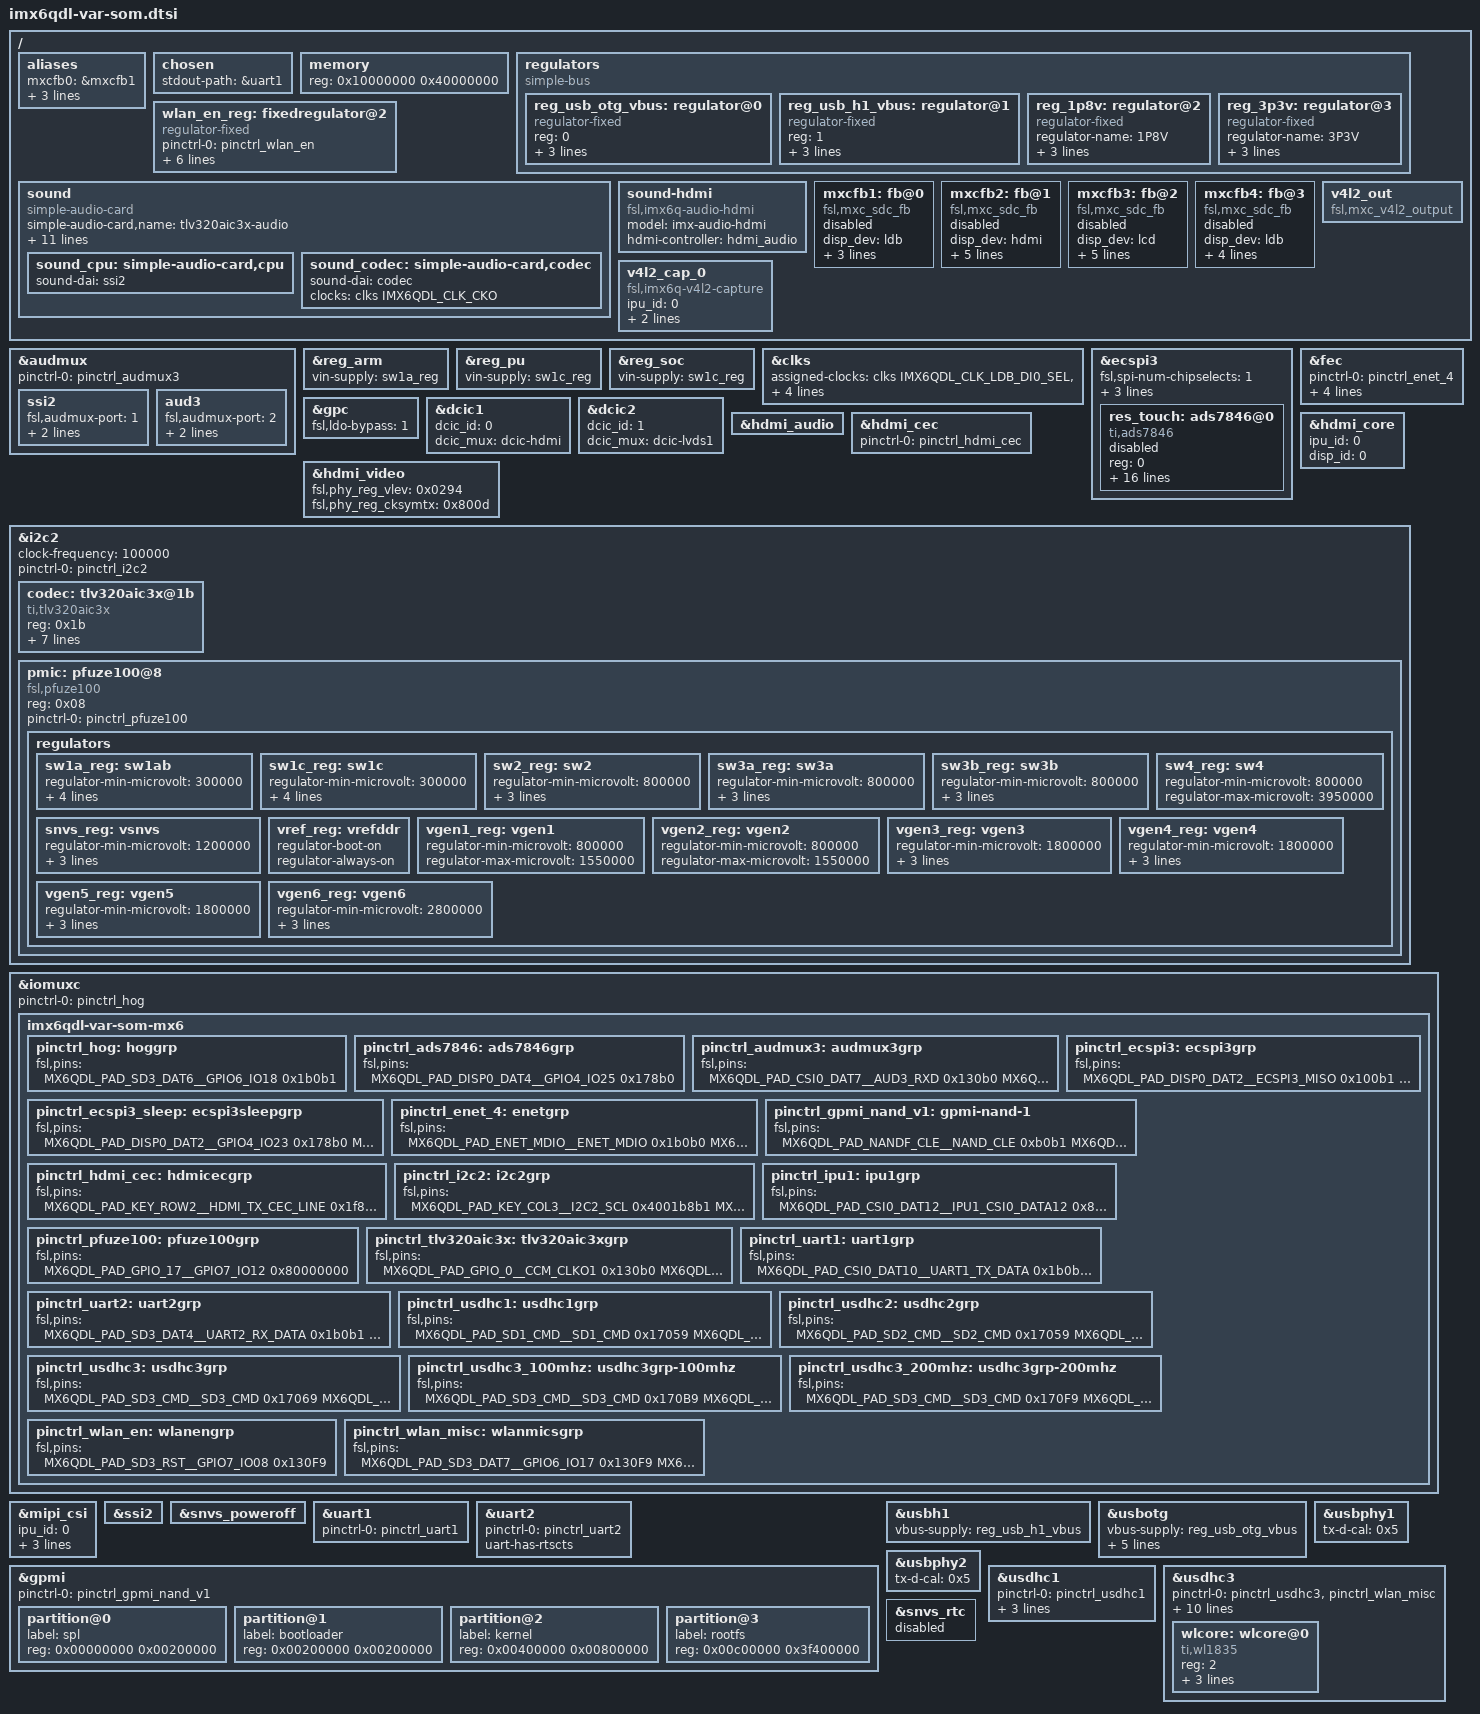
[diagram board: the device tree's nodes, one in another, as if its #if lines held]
/*
 * Copyright (C) 2015-2017 Variscite Ltd.
 *
 * This program is free software; you can redistribute it and/or modify
 * it under the terms of the GNU General Public License version 2 as
 * published by the Free Software Foundation.
 */

#include <dt-bindings/gpio/gpio.h>
#include <dt-bindings/input/input.h>
#include <dt-bindings/sound/fsl-imx-audmux.h>

/ {
	aliases {
		mxcfb0 = &mxcfb1;
		mxcfb1 = &mxcfb2;
		mxcfb2 = &mxcfb3;
		mxcfb3 = &mxcfb4;
	};

	chosen {
		stdout-path = &uart1;
	};

	memory: memory {
		reg = <0x10000000 0x40000000>;
	};

	regulators {
		compatible = "simple-bus";
		#address-cells = <1>;
		#size-cells = <0>;

		reg_usb_otg_vbus: regulator@0 {
			compatible = "regulator-fixed";
			reg = <0>;
			regulator-name = "usb_otg_vbus";
			regulator-min-microvolt = <5000000>;
			regulator-max-microvolt = <5000000>;
		};

		reg_usb_h1_vbus: regulator@1 {
			compatible = "regulator-fixed";
			reg = <1>;
			regulator-name = "usb_h1_vbus";
			regulator-min-microvolt = <5000000>;
			regulator-max-microvolt = <5000000>;
		};

		reg_1p8v: regulator@2 {
			compatible = "regulator-fixed";
			regulator-name = "1P8V";
			regulator-min-microvolt = <1800000>;
			regulator-max-microvolt = <1800000>;
			regulator-always-on;
		};

		reg_3p3v: regulator@3 {
			compatible = "regulator-fixed";
			regulator-name = "3P3V";
			regulator-min-microvolt = <3300000>;
			regulator-max-microvolt = <3300000>;
			regulator-always-on;
		};
	};

	wlan_en_reg: fixedregulator@2 {
		compatible = "regulator-fixed";
		pinctrl-names = "default";
		pinctrl-0 = <&pinctrl_wlan_en>;
		regulator-name = "wlan-en-regulator";
		regulator-min-microvolt = <1800000>;
		regulator-max-microvolt = <1800000>;

		/* WLAN_EN GPIO for this board - Bank5, pin13 */
		gpio = <&gpio7 8 0>;

		/* WLAN card specific delay */
		startup-delay-us = <70000>;
		enable-active-high;
	};

	sound {
		compatible = "simple-audio-card";
		simple-audio-card,name = "tlv320aic3x-audio";
		simple-audio-card,format = "i2s";
		simple-audio-card,bitclock-master = <&sound_codec>;
		simple-audio-card,frame-master = <&sound_codec>;
		simple-audio-card,widgets = "Headphone", "Headphone Jack",
					    "Line", "Line In Jack",
					    "Microphone", "DMic";
#ifdef HAVE_AUDIO_ENABLE_GPIO
		/* Sample use of gpio controlled amplifier:
		 * this is extremely useful to avoid the bump effect
		 * observed when connecting an amplifier to the HP OUT.
		 * The property "pa-gpios" must provide the enable GPIO.
		 */
		pa-gpios = <&gpio5 30 GPIO_ACTIVE_HIGH>;
		simple-audio-card,routing = "Headphone Jack", "Amplifier",
					    "Amplifier", "HPLOUT",
					    "Amplifier", "HPROUT",
					    "LINE1L", "Line In Jack",
					    "LINE1R", "Line In Jack",
					    "DMIC", "DMic";
#else
		simple-audio-card,routing = "Headphone Jack", "HPLOUT",
					    "Headphone Jack", "HPROUT",
					    "LINE1L", "Line In Jack",
					    "LINE1R", "Line In Jack",
					    "DMIC", "DMic";
#endif
		sound_cpu: simple-audio-card,cpu {
			sound-dai = <&ssi2>;
		};

		sound_codec: simple-audio-card,codec {
			sound-dai = <&codec>;
			clocks = <&clks IMX6QDL_CLK_CKO>;
		};
	};

	sound-hdmi {
		compatible = "fsl,imx6q-audio-hdmi",
			     "fsl,imx-audio-hdmi";
		model = "imx-audio-hdmi";
		hdmi-controller = <&hdmi_audio>;
	};

	mxcfb1: fb@0 {
		compatible = "fsl,mxc_sdc_fb";
		disp_dev = "ldb";
		default_bpp = <16>;
		int_clk = <0>;
		late_init = <0>;
		status = "disabled";
	};

	mxcfb2: fb@1 {
		compatible = "fsl,mxc_sdc_fb";
		disp_dev = "hdmi";
		interface_pix_fmt = "RGB24";
		mode_str ="1920x1080M@60";
		default_bpp = <24>;
		int_clk = <0>;
		late_init = <0>;
		status = "disabled";
	};

	mxcfb3: fb@2 {
		compatible = "fsl,mxc_sdc_fb";
		disp_dev = "lcd";
		interface_pix_fmt = "RGB565";
		mode_str ="CLAA-WVGA";
		default_bpp = <16>;
		int_clk = <0>;
		late_init = <0>;
		status = "disabled";
	};

	mxcfb4: fb@3 {
		compatible = "fsl,mxc_sdc_fb";
		disp_dev = "ldb";
		interface_pix_fmt = "RGB666";
		default_bpp = <16>;
		int_clk = <0>;
		late_init = <0>;
		status = "disabled";
	};

	v4l2_cap_0 {
		compatible = "fsl,imx6q-v4l2-capture";
		ipu_id = <0>;
		csi_id = <1>;
		mclk_source = <0>;
		status = "okay";
	};

	v4l2_out {
		compatible = "fsl,mxc_v4l2_output";
		status = "okay";
	};
};

&audmux {
	pinctrl-names = "default";
	pinctrl-0 = <&pinctrl_audmux3>;
	status = "okay";

	ssi2 {
		fsl,audmux-port = <1>;
		fsl,port-config = <
			(IMX_AUDMUX_V2_PTCR_SYN |
			IMX_AUDMUX_V2_PTCR_TFSDIR |
			IMX_AUDMUX_V2_PTCR_TFSEL(2) |
			IMX_AUDMUX_V2_PTCR_TCLKDIR |
			IMX_AUDMUX_V2_PTCR_TCSEL(2))
			IMX_AUDMUX_V2_PDCR_RXDSEL(2)
		>;
	};

	aud3 {
		fsl,audmux-port = <2>;
		fsl,port-config = <
			IMX_AUDMUX_V2_PTCR_SYN
			IMX_AUDMUX_V2_PDCR_RXDSEL(1)
		>;
	};
};

&reg_arm {
	vin-supply = <&sw1a_reg>;
};

&reg_pu {
	vin-supply = <&sw1c_reg>;
};

&reg_soc {
	vin-supply = <&sw1c_reg>;
};

&clks {
	assigned-clocks = <&clks IMX6QDL_CLK_LDB_DI0_SEL>,
			  <&clks IMX6QDL_CLK_LDB_DI1_SEL>;
	assigned-clock-parents = <&clks IMX6QDL_CLK_PLL2_PFD0_352M>,
				 <&clks IMX6QDL_CLK_PLL2_PFD0_352M>;
};

&ecspi3 {
	fsl,spi-num-chipselects = <1>;
	pinctrl-names = "default", "sleep";
	pinctrl-0 = <&pinctrl_ecspi3>;
	pinctrl-1 = <&pinctrl_ecspi3_sleep>;
	cs-gpios = <&gpio4 24 0>;
	status = "okay";

	/* Touch */
	res_touch: ads7846@0 {
		reg = <0>;	/* CS0 */
		compatible = "ti,ads7846";
		pinctrl-names = "default";
		pinctrl-0 = <&pinctrl_ads7846>;
		interrupt-parent = <&gpio4>;
		interrupts = <25 0>;
		spi-max-frequency = <1500000>;
		pendown-gpio = <&gpio4 25 0>;
		ti,x-min = /bits/ 16 <125>;
		ti,x-max = /bits/ 16 <4008>;
		ti,y-min = /bits/ 16 <282>;
		ti,y-max = /bits/ 16 <3864>;
		ti,x-plate-ohms = /bits/ 16 <180>;
		ti,pressure-max = /bits/ 16 <255>;
		ti,debounce-max = /bits/ 16 <10>;
		ti,debounce-tol = /bits/ 16 <3>;
		ti,debounce-rep = /bits/ 16 <1>;
		ti,settle-delay-usec = /bits/ 16 <150>;
		ti,keep-vref-on;
		status = "disabled";
	};
};

&fec {
	pinctrl-names = "default";
	pinctrl-0 = <&pinctrl_enet_4>;
	phy-mode = "rgmii";
	phy-reset-gpios = <&gpio1 25 0>;
	phy-reset-duration=<100>;
	phy-reset-on-resume;
	status = "okay";
};

&gpc {
	/* use ldo-bypass, u-boot will check it and configure */
	fsl,ldo-bypass = <1>;
};

&dcic1 {
	dcic_id = <0>;
	dcic_mux = "dcic-hdmi";
	status = "okay";
};

&dcic2 {
	dcic_id = <1>;
	dcic_mux = "dcic-lvds1";
	status = "okay";
};

&hdmi_audio {
	status = "okay";
};

&hdmi_cec {
	pinctrl-names = "default";
	pinctrl-0 = <&pinctrl_hdmi_cec>;
	status = "okay";
};

&hdmi_core {
	ipu_id = <0>;
	disp_id = <0>;
	status = "okay";
};

&hdmi_video {
	fsl,phy_reg_vlev = <0x0294>;
	fsl,phy_reg_cksymtx = <0x800d>;
	status = "okay";
};

&i2c2 {
	clock-frequency = <100000>;
	pinctrl-names = "default";
	pinctrl-0 = <&pinctrl_i2c2>;
	status = "okay";

	codec: tlv320aic3x@1b {
		compatible = "ti,tlv320aic3x";
		reg = <0x1b>;
		#sound-dai-cells = <0>;
		pinctrl-names = "default";
		pinctrl-0 = <&pinctrl_tlv320aic3x>;
		IOVDD-supply = <&reg_3p3v>;
		DVDD-supply = <&reg_1p8v>;
		AVDD-supply = <&reg_3p3v>;
		DRVDD-supply = <&reg_3p3v>;
		reset-gpios = <&gpio4 5 GPIO_ACTIVE_LOW>;
		ai3x-gpio-func = <
			0 /* AIC3X_GPIO1_FUNC_DISABLED */
			5 /* AIC3X_GPIO2_FUNC_DIGITAL_MIC_INPUT */
		>;
	};

	pmic: pfuze100@8 {
		compatible = "fsl,pfuze100";
		reg = <0x08>;
		pinctrl-names = "default";
		pinctrl-0 = <&pinctrl_pfuze100>;

		regulators {
			sw1a_reg: sw1ab {
				regulator-min-microvolt = <300000>;
				regulator-max-microvolt = <1875000>;
				regulator-boot-on;
				regulator-always-on;
				regulator-ramp-delay = <6250>;
			};

			sw1c_reg: sw1c {
				regulator-min-microvolt = <300000>;
				regulator-max-microvolt = <1875000>;
				regulator-boot-on;
				regulator-always-on;
				regulator-ramp-delay = <6250>;
			};

			sw2_reg: sw2 {
				regulator-min-microvolt = <800000>;
				regulator-max-microvolt = <3300000>;
				regulator-boot-on;
				regulator-always-on;
			};

			sw3a_reg: sw3a {
				regulator-min-microvolt = <800000>;
				regulator-max-microvolt = <3950000>;
				regulator-boot-on;
				regulator-always-on;
			};

			sw3b_reg: sw3b {
				regulator-min-microvolt = <800000>;
				regulator-max-microvolt = <3950000>;
				regulator-boot-on;
				regulator-always-on;
			};

			sw4_reg: sw4 {
				regulator-min-microvolt = <800000>;
				regulator-max-microvolt = <3950000>;
			};

			snvs_reg: vsnvs {
				regulator-min-microvolt = <1200000>;
				regulator-max-microvolt = <3000000>;
				regulator-boot-on;
				regulator-always-on;
			};

			vref_reg: vrefddr {
				regulator-boot-on;
				regulator-always-on;
			};

			vgen1_reg: vgen1 {
				regulator-min-microvolt = <800000>;
				regulator-max-microvolt = <1550000>;
			};

			vgen2_reg: vgen2 {
				regulator-min-microvolt = <800000>;
				regulator-max-microvolt = <1550000>;
			};

			vgen3_reg: vgen3 {
				regulator-min-microvolt = <1800000>;
				regulator-max-microvolt = <3300000>;
				regulator-always-on;
				regulator-boot-on;
			};

			vgen4_reg: vgen4 {
				regulator-min-microvolt = <1800000>;
				regulator-max-microvolt = <3300000>;
				regulator-always-on;
				regulator-boot-on;
			};

			vgen5_reg: vgen5 {
				regulator-min-microvolt = <1800000>;
				regulator-max-microvolt = <3300000>;
				regulator-always-on;
				regulator-boot-on;
			};

			vgen6_reg: vgen6 {
				regulator-min-microvolt = <2800000>;
				regulator-max-microvolt = <2800000>;
				regulator-always-on;
				regulator-boot-on;
			};
		};
	};
};

&iomuxc {
	pinctrl-names = "default";
	pinctrl-0 = <&pinctrl_hog>;

	imx6qdl-var-som-mx6 {

		pinctrl_hog: hoggrp {
			fsl,pins = <
				/* for Bluetooth enable */
				MX6QDL_PAD_SD3_DAT6__GPIO6_IO18		0x1b0b1
			>;
		};

		pinctrl_ads7846: ads7846grp {
			fsl,pins = <
				/* Resistive touch irq */
				MX6QDL_PAD_DISP0_DAT4__GPIO4_IO25	0x178b0
			>;
		};

		pinctrl_audmux3: audmux3grp {
			fsl,pins = <
				MX6QDL_PAD_CSI0_DAT7__AUD3_RXD		0x130b0
				MX6QDL_PAD_CSI0_DAT4__AUD3_TXC		0x130b0
				MX6QDL_PAD_CSI0_DAT5__AUD3_TXD		0x110b0
				MX6QDL_PAD_CSI0_DAT6__AUD3_TXFS		0x130b0
			>;
		};

		pinctrl_ecspi3: ecspi3grp {
			fsl,pins = <
				MX6QDL_PAD_DISP0_DAT2__ECSPI3_MISO	0x100b1
				MX6QDL_PAD_DISP0_DAT1__ECSPI3_MOSI	0x100b1
				MX6QDL_PAD_DISP0_DAT0__ECSPI3_SCLK	0x100b1
				MX6QDL_PAD_DISP0_DAT3__GPIO4_IO24	0x178b0 /* CS */
			>;
		};

		pinctrl_ecspi3_sleep: ecspi3sleepgrp {
			fsl,pins = <
				MX6QDL_PAD_DISP0_DAT2__GPIO4_IO23	0x178b0
				MX6QDL_PAD_DISP0_DAT1__GPIO4_IO22	0x178b0
				MX6QDL_PAD_DISP0_DAT0__GPIO4_IO21	0x178b0
				MX6QDL_PAD_DISP0_DAT3__GPIO4_IO24	0x178b0 /* CS */
			>;
		};

		pinctrl_enet_4: enetgrp {
			fsl,pins = <
				MX6QDL_PAD_ENET_MDIO__ENET_MDIO		0x1b0b0
				MX6QDL_PAD_ENET_MDC__ENET_MDC		0x1b0b0
				MX6QDL_PAD_RGMII_TXC__RGMII_TXC		0x1b0b0
				MX6QDL_PAD_RGMII_TD0__RGMII_TD0		0x1b0b0
				MX6QDL_PAD_RGMII_TD1__RGMII_TD1		0x1b0b0
				MX6QDL_PAD_RGMII_TD2__RGMII_TD2		0x1b0b0
				MX6QDL_PAD_RGMII_TD3__RGMII_TD3		0x1b0b0
				MX6QDL_PAD_RGMII_TX_CTL__RGMII_TX_CTL	0x1b0b0
				MX6QDL_PAD_ENET_REF_CLK__ENET_TX_CLK	0x1b0b0
				MX6QDL_PAD_RGMII_RXC__RGMII_RXC		0x1b0b0
				MX6QDL_PAD_RGMII_RD0__RGMII_RD0		0x1b0b0
				MX6QDL_PAD_RGMII_RD1__RGMII_RD1		0x1b0b0
				MX6QDL_PAD_RGMII_RD2__RGMII_RD2		0x1b0b0
				MX6QDL_PAD_RGMII_RD3__RGMII_RD3		0x1b0b0
				MX6QDL_PAD_RGMII_RX_CTL__RGMII_RX_CTL	0x1b0b0
				MX6QDL_PAD_ENET_CRS_DV__GPIO1_IO25	0x1b0b0
			>;
		};

		pinctrl_gpmi_nand_v1: gpmi-nand-1 {
			fsl,pins = <
				MX6QDL_PAD_NANDF_CLE__NAND_CLE		0xb0b1
				MX6QDL_PAD_NANDF_ALE__NAND_ALE		0xb0b1
				MX6QDL_PAD_NANDF_CS0__NAND_CE0_B	0xb0b1
				MX6QDL_PAD_NANDF_CS1__NAND_CE1_B	0xb0b1
				MX6QDL_PAD_NANDF_RB0__NAND_READY_B	0xb0b1
				MX6QDL_PAD_NANDF_D0__NAND_DATA00	0xb0b1
				MX6QDL_PAD_NANDF_D1__NAND_DATA01	0xb0b1
				MX6QDL_PAD_NANDF_D2__NAND_DATA02	0xb0b1
				MX6QDL_PAD_NANDF_D3__NAND_DATA03	0xb0b1
				MX6QDL_PAD_NANDF_D4__NAND_DATA04	0xb0b1
				MX6QDL_PAD_NANDF_D5__NAND_DATA05	0xb0b1
				MX6QDL_PAD_NANDF_D6__NAND_DATA06	0xb0b1
				MX6QDL_PAD_NANDF_D7__NAND_DATA07	0xb0b1
				MX6QDL_PAD_SD4_CMD__NAND_RE_B		0xb0b1
				MX6QDL_PAD_SD4_CLK__NAND_WE_B		0xb0b1
				MX6QDL_PAD_NANDF_WP_B__NAND_WP_B	0xb0b1
			>;
		};

		pinctrl_hdmi_cec: hdmicecgrp {
			fsl,pins = <
				MX6QDL_PAD_KEY_ROW2__HDMI_TX_CEC_LINE	0x1f8b0
			>;
		};

		pinctrl_i2c2: i2c2grp {
			fsl,pins = <
				MX6QDL_PAD_KEY_COL3__I2C2_SCL		0x4001b8b1
				MX6QDL_PAD_KEY_ROW3__I2C2_SDA		0x4001b8b1
			>;
		};

		pinctrl_ipu1: ipu1grp { /* parallel camera */
			fsl,pins = <
				MX6QDL_PAD_CSI0_DAT12__IPU1_CSI0_DATA12		0x80000000
				MX6QDL_PAD_CSI0_DAT13__IPU1_CSI0_DATA13		0x80000000
				MX6QDL_PAD_CSI0_DAT14__IPU1_CSI0_DATA14		0x80000000
				MX6QDL_PAD_CSI0_DAT15__IPU1_CSI0_DATA15		0x80000000
				MX6QDL_PAD_CSI0_DAT16__IPU1_CSI0_DATA16		0x80000000
				MX6QDL_PAD_CSI0_DAT17__IPU1_CSI0_DATA17		0x80000000
				MX6QDL_PAD_CSI0_DAT18__IPU1_CSI0_DATA18		0x80000000
				MX6QDL_PAD_CSI0_DAT19__IPU1_CSI0_DATA19		0x80000000
				MX6QDL_PAD_CSI0_DATA_EN__IPU1_CSI0_DATA_EN	0x80000000
				MX6QDL_PAD_CSI0_PIXCLK__IPU1_CSI0_PIXCLK	0x80000000
				MX6QDL_PAD_CSI0_MCLK__IPU1_CSI0_HSYNC		0x80000000
				MX6QDL_PAD_CSI0_VSYNC__IPU1_CSI0_VSYNC		0x80000000
			>;
		};

		pinctrl_pfuze100: pfuze100grp {
			fsl,pins = <
				/* PMIC INT */
				MX6QDL_PAD_GPIO_17__GPIO7_IO12		0x80000000
			>;
		};

		pinctrl_tlv320aic3x: tlv320aic3xgrp {
			fsl,pins = <
				/* Audio Clock */
				MX6QDL_PAD_GPIO_0__CCM_CLKO1		0x130b0
				/* Audio reset */
				MX6QDL_PAD_GPIO_19__GPIO4_IO05		0x178b0
			>;
		};

		/* Linux Console */
		pinctrl_uart1: uart1grp { /* RX/TX only */
			fsl,pins = <
				MX6QDL_PAD_CSI0_DAT10__UART1_TX_DATA	0x1b0b1
				MX6QDL_PAD_CSI0_DAT11__UART1_RX_DATA	0x1b0b1
			>;
		};

		/* Variscite Bluetooth */
		pinctrl_uart2: uart2grp { /* RTS/CTS only mode */
			fsl,pins = <
				MX6QDL_PAD_SD3_DAT4__UART2_RX_DATA	0x1b0b1
				MX6QDL_PAD_SD3_DAT5__UART2_TX_DATA	0x1b0b1
				MX6QDL_PAD_EIM_D28__UART2_CTS_B		0x1b0b1
				MX6QDL_PAD_EIM_D29__UART2_RTS_B		0x1b0b1
			>;
		};

		pinctrl_usdhc1: usdhc1grp {
			fsl,pins = <
				MX6QDL_PAD_SD1_CMD__SD1_CMD		0x17059
				MX6QDL_PAD_SD1_CLK__SD1_CLK		0x10059
				MX6QDL_PAD_SD1_DAT0__SD1_DATA0		0x17059
				MX6QDL_PAD_SD1_DAT1__SD1_DATA1		0x17059
				MX6QDL_PAD_SD1_DAT2__SD1_DATA2		0x17059
				MX6QDL_PAD_SD1_DAT3__SD1_DATA3		0x17059
			>;
		};

		pinctrl_usdhc2: usdhc2grp {
			fsl,pins = <
				MX6QDL_PAD_SD2_CMD__SD2_CMD		0x17059
				MX6QDL_PAD_SD2_CLK__SD2_CLK		0x10059
				MX6QDL_PAD_SD2_DAT0__SD2_DATA0		0x17059
				MX6QDL_PAD_SD2_DAT1__SD2_DATA1		0x17059
				MX6QDL_PAD_SD2_DAT2__SD2_DATA2		0x17059
				MX6QDL_PAD_SD2_DAT3__SD2_DATA3		0x17059
			>;
		};

		pinctrl_usdhc3: usdhc3grp {
			fsl,pins = <
				MX6QDL_PAD_SD3_CMD__SD3_CMD		0x17069
				MX6QDL_PAD_SD3_CLK__SD3_CLK		0x10069
				MX6QDL_PAD_SD3_DAT0__SD3_DATA0		0x17069
				MX6QDL_PAD_SD3_DAT1__SD3_DATA1		0x17069
				MX6QDL_PAD_SD3_DAT2__SD3_DATA2		0x17069
				MX6QDL_PAD_SD3_DAT3__SD3_DATA3		0x17069
			>;
		};

		pinctrl_usdhc3_100mhz: usdhc3grp-100mhz {
			fsl,pins = <
				MX6QDL_PAD_SD3_CMD__SD3_CMD		0x170B9
				MX6QDL_PAD_SD3_CLK__SD3_CLK		0x100B9
				MX6QDL_PAD_SD3_DAT0__SD3_DATA0		0x170B9
				MX6QDL_PAD_SD3_DAT1__SD3_DATA1		0x170B9
				MX6QDL_PAD_SD3_DAT2__SD3_DATA2		0x170B9
				MX6QDL_PAD_SD3_DAT3__SD3_DATA3		0x170B9
			>;
		};

		pinctrl_usdhc3_200mhz: usdhc3grp-200mhz {
			fsl,pins = <
				MX6QDL_PAD_SD3_CMD__SD3_CMD		0x170F9
				MX6QDL_PAD_SD3_CLK__SD3_CLK		0x100F9
				MX6QDL_PAD_SD3_DAT0__SD3_DATA0		0x170F9
				MX6QDL_PAD_SD3_DAT1__SD3_DATA1		0x170F9
				MX6QDL_PAD_SD3_DAT2__SD3_DATA2		0x170F9
				MX6QDL_PAD_SD3_DAT3__SD3_DATA3		0x170F9
			>;
		};

		pinctrl_wlan_en: wlanengrp {
			fsl,pins = <
				/* for wifi enable */
				MX6QDL_PAD_SD3_RST__GPIO7_IO08		0x130F9
			>;
		};

		pinctrl_wlan_misc: wlanmicsgrp {
			fsl,pins = <
				/* for wifi irq */
				MX6QDL_PAD_SD3_DAT7__GPIO6_IO17		0x130F9
				/* Wifi Slow Clock */
				MX6QDL_PAD_ENET_RXD0__OSC32K_32K_OUT	0x000b0
			>;
		};
	};
};

&mipi_csi {
	status = "okay";
	ipu_id = <0>;
	csi_id = <1>;
	v_channel = <0>;
	lanes = <2>;
};

&ssi2 {
	status = "okay";
};

&snvs_poweroff {
	status = "okay";
};

/* Console Uart */
&uart1 {
	pinctrl-names = "default";
	pinctrl-0 = <&pinctrl_uart1>;
	status = "okay";
};

/* Bluetooth Uart */
&uart2 {
	pinctrl-names = "default";
	pinctrl-0 = <&pinctrl_uart2>;
	uart-has-rtscts;
	status = "okay";
};

&gpmi {
	pinctrl-names = "default";
	pinctrl-0 = <&pinctrl_gpmi_nand_v1>;
	status = "okay";

	/* a 2 MiB partition */
	partition@0 {
		label = "spl";
		reg = <0x00000000 0x00200000>;
	};

	/* a 2 MiB partition */
	partition@1 {
		label = "bootloader";
		reg = <0x00200000 0x00200000>;
	};

	/* an 8 MiB partition */
	partition@2 {
		label = "kernel";
		reg = <0x00400000 0x00800000>;
	};

	/* a 1012 MiB partition */
	partition@3 {
		label = "rootfs";
		reg = <0x00c00000 0x3f400000>;
	};
};

&usbh1 {
	vbus-supply = <&reg_usb_h1_vbus>;
	status = "okay";
};

&usbotg {
	vbus-supply = <&reg_usb_otg_vbus>;
	disable-over-current;
	/* dr_mode: One of "host", "peripheral" or "otg". Defaults to "otg" */
	dr_mode = "host";
	srp-disable;
	hnp-disable;
	adp-disable;
	status = "okay";
};

&usbphy1 {
	tx-d-cal = <0x5>;
};

&usbphy2 {
	tx-d-cal = <0x5>;
};

&usdhc1 {	/* uSDHC1, eMMC */
	pinctrl-names = "default";
	pinctrl-0 = <&pinctrl_usdhc1>;
	non-removable;
	keep-power-in-suspend;
	enable-sdio-wakeup;
	status = "okay";
};

&usdhc3 {	/* uSDHC3, TiWi wl1271 7 Wilink8 WL18xx*/
	pinctrl-names = "default", "state_100mhz", "state_200mhz";
	pinctrl-0 = <&pinctrl_usdhc3>, <&pinctrl_wlan_misc>;
	pinctrl-1 = <&pinctrl_usdhc3_100mhz>, <&pinctrl_wlan_misc>;
	pinctrl-2 = <&pinctrl_usdhc3_200mhz>, <&pinctrl_wlan_misc>;
	keep-power-in-suspend;
	enable-sdio-wakeup;
	vmmc-supply = <&wlan_en_reg>;
	bus-width = <4>;
	non-removable;
	cap-power-off-card;
	status = "okay";
	#address-cells = <1>;
	#size-cells = <0>;
	wlcore: wlcore@0 {
		compatible = "ti,wl1835";
		reg = <2>;
		interrupt-parent = <&gpio6>;
		interrupts = <17 IRQ_TYPE_EDGE_RISING>;

		/* if a 12xx card is there, configure the clock to WL12XX_REFCLOCK_38_XTAL */
		ref-clock-frequency = <38400000>;
	};
};

&snvs_rtc {
	status = "disabled";
};
